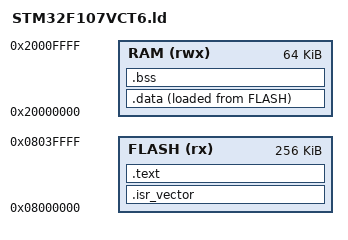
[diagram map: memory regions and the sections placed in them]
/* STM32F107VCT6 : 256 KB flash, 64 KB SRAM */

ENTRY(Reset_Handler)

_estack = 0x20010000;          /* top of 64 KB SRAM */

MEMORY
{
  FLASH (rx)  : ORIGIN = 0x08000000, LENGTH = 256K
  RAM   (rwx) : ORIGIN = 0x20000000, LENGTH = 64K
}

SECTIONS
{
  .isr_vector : { KEEP(*(.isr_vector)) } > FLASH

  .text :
  {
    *(.text*)
    *(.rodata*)
    . = ALIGN(4);
  } > FLASH

  . = ALIGN(4);
  _sidata = LOADADDR(.data);

  .data :
  {
    . = ALIGN(4);
    _sdata = .;
    *(.data*)
    . = ALIGN(4);
    _edata = .;
  } > RAM AT > FLASH

  .bss :
  {
    . = ALIGN(4);
    _sbss = .;
    *(.bss*)
    *(COMMON)
    . = ALIGN(4);
    _ebss = .;
  } > RAM

  /DISCARD/ : { *(.ARM.exidx*) }
}
